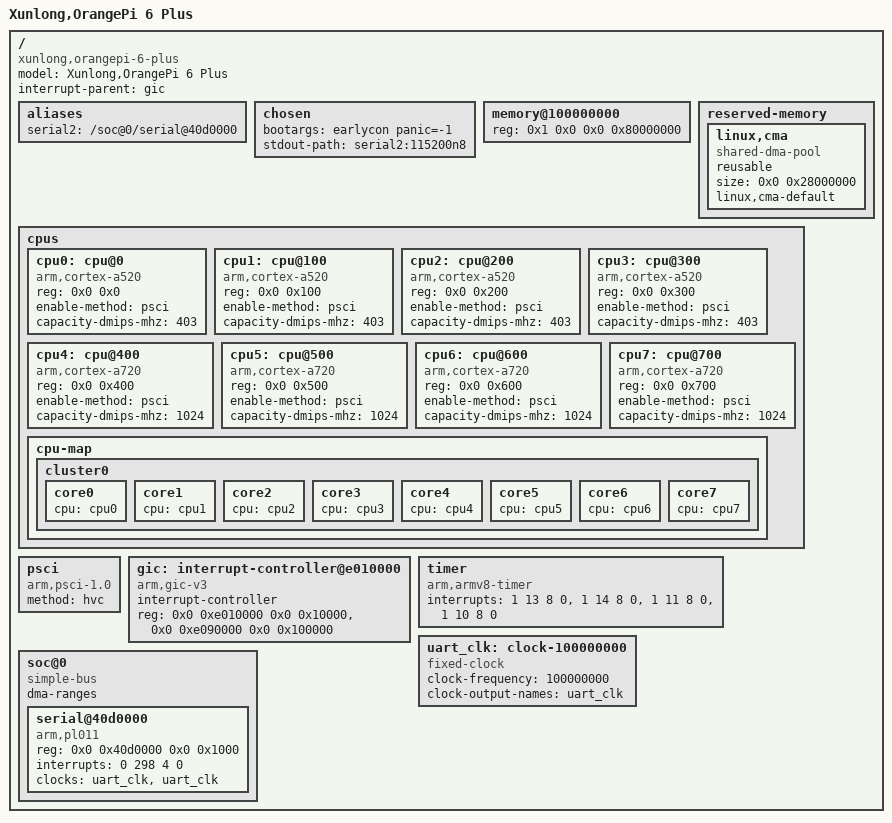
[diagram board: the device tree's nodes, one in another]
/dts-v1/;

// Partition A (Linux) of HAVEN on the Orange Pi 6 Plus (CIX P1). GENERATED, do not edit:
// docs/methodology/stage2/20261109-board-partition-tree/gen_partition_a.py
// from Linux v7.3 sky1-xcp.dts sha256 cc96c9c9ccbbb6955e5e84b837103810b12194816e85807864a5a19c012f894c
// and sky1.dtsi sha256 386626c419330751db71a19818813c93c1d647bc6281b62483105045bb433149
// with grant grant-cixp1-v0.json sha256 6d59ef82ae042cf44d2f4383351336dce5cebedf8f04a76102d3308a97ece9d8
// SEEDED FAULT S5 (README.md, Expectations): not a tree to boot

/ {
	model = "Xunlong,OrangePi 6 Plus";
	compatible = "xunlong,orangepi-6-plus", "cix,sky1";
	#address-cells = <2>;
	#size-cells = <2>;
	interrupt-parent = <&gic>;

	aliases {
		serial2 = "/soc@0/serial@40d0000";
	};

	chosen {
		bootargs = "earlycon panic=-1";
		stdout-path = "serial2:115200n8";
	};

	memory@100000000 {
		device_type = "memory";
		reg = <0x1 0x0 0x0 0x80000000>;
	};

	reserved-memory {
		#address-cells = <2>;
		#size-cells = <2>;
		ranges;

		linux,cma {
			compatible = "shared-dma-pool";
			reusable;
			size = <0x0 0x28000000>;
			linux,cma-default;
		};
	};

	cpus {
		#address-cells = <2>;
		#size-cells = <0>;

		cpu0: cpu@0 {
			device_type = "cpu";
			compatible = "arm,cortex-a520";
			reg = <0x0 0x0>;
			enable-method = "psci";
			capacity-dmips-mhz = <403>;
		};

		cpu1: cpu@100 {
			device_type = "cpu";
			compatible = "arm,cortex-a520";
			reg = <0x0 0x100>;
			enable-method = "psci";
			capacity-dmips-mhz = <403>;
		};

		cpu2: cpu@200 {
			device_type = "cpu";
			compatible = "arm,cortex-a520";
			reg = <0x0 0x200>;
			enable-method = "psci";
			capacity-dmips-mhz = <403>;
		};

		cpu3: cpu@300 {
			device_type = "cpu";
			compatible = "arm,cortex-a520";
			reg = <0x0 0x300>;
			enable-method = "psci";
			capacity-dmips-mhz = <403>;
		};

		cpu4: cpu@400 {
			device_type = "cpu";
			compatible = "arm,cortex-a720";
			reg = <0x0 0x400>;
			enable-method = "psci";
			capacity-dmips-mhz = <1024>;
		};

		cpu5: cpu@500 {
			device_type = "cpu";
			compatible = "arm,cortex-a720";
			reg = <0x0 0x500>;
			enable-method = "psci";
			capacity-dmips-mhz = <1024>;
		};

		cpu6: cpu@600 {
			device_type = "cpu";
			compatible = "arm,cortex-a720";
			reg = <0x0 0x600>;
			enable-method = "psci";
			capacity-dmips-mhz = <1024>;
		};

		cpu7: cpu@700 {
			device_type = "cpu";
			compatible = "arm,cortex-a720";
			reg = <0x0 0x700>;
			enable-method = "psci";
			capacity-dmips-mhz = <1024>;
		};

		cpu-map {
			cluster0 {
				core0 {
					cpu = <&cpu0>;
				};

				core1 {
					cpu = <&cpu1>;
				};

				core2 {
					cpu = <&cpu2>;
				};

				core3 {
					cpu = <&cpu3>;
				};

				core4 {
					cpu = <&cpu4>;
				};

				core5 {
					cpu = <&cpu5>;
				};

				core6 {
					cpu = <&cpu6>;
				};

				core7 {
					cpu = <&cpu7>;
				};
			};
		};
	};

	psci {
		compatible = "arm,psci-1.0", "arm,psci-0.2";
		method = "hvc";
	};

	gic: interrupt-controller@e010000 {
		compatible = "arm,gic-v3";
		#interrupt-cells = <4>;
		#address-cells = <0>;
		interrupt-controller;
		reg = <0x0 0xe010000 0x0 0x10000>, <0x0 0xe090000 0x0 0x100000>;
	};

	timer {
		compatible = "arm,armv8-timer";
		interrupts = <1 13 8 0>, <1 14 8 0>, <1 11 8 0>, <1 10 8 0>;
	};

	uart_clk: clock-100000000 {
		compatible = "fixed-clock";
		#clock-cells = <0>;
		clock-frequency = <100000000>;
		clock-output-names = "uart_clk";
	};

	soc@0 {
		compatible = "simple-bus";
		ranges = <0x0 0x0 0x0 0x0 0x20 0x0>;
		dma-ranges;
		#address-cells = <2>;
		#size-cells = <2>;

		serial@40d0000 {
			compatible = "arm,pl011", "arm,primecell";
			reg = <0x0 0x40d0000 0x0 0x1000>;
			interrupts = <0 298 4 0>;
			clocks = <&uart_clk>, <&uart_clk>;
			clock-names = "uartclk", "apb_pclk";
			status = "okay";
		};
	};
};
